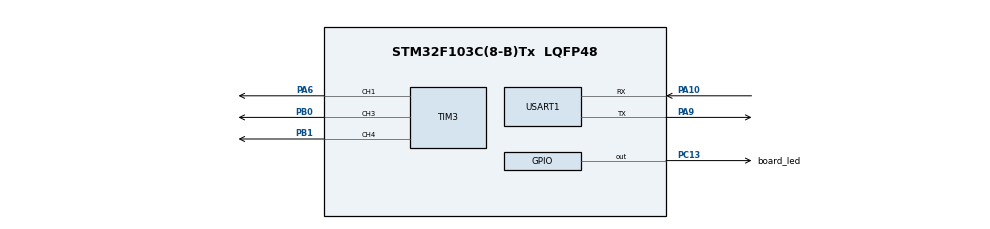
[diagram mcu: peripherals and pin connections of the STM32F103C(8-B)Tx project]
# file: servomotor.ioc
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Dma.Request0=TIM3_CH4/UP
Dma.TIM3_CH4/UP.0.Direction=DMA_PERIPH_TO_MEMORY
Dma.TIM3_CH4/UP.0.Instance=DMA1_Channel3
Dma.TIM3_CH4/UP.0.MemDataAlignment=DMA_MDATAALIGN_HALFWORD
Dma.TIM3_CH4/UP.0.MemInc=DMA_MINC_ENABLE
Dma.TIM3_CH4/UP.0.Mode=DMA_CIRCULAR
Dma.TIM3_CH4/UP.0.PeriphDataAlignment=DMA_PDATAALIGN_HALFWORD
Dma.TIM3_CH4/UP.0.PeriphInc=DMA_PINC_DISABLE
Dma.TIM3_CH4/UP.0.Priority=DMA_PRIORITY_LOW
Mcu.Family=STM32F1
Mcu.Name=STM32F103C(8-B)Tx
Mcu.Package=LQFP48
NVIC.DMA1_Channel3_IRQn=true\:0\:0\:false\:false\:true\:false\:true
NVIC.PriorityGroup=NVIC_PRIORITYGROUP_4
PA10.Mode=Asynchronous
PA10.Signal=USART1_RX
PA13.Mode=Serial_Wire
PA13.Signal=SYS_JTMS-SWDIO
PA14.Mode=Serial_Wire
PA14.Signal=SYS_JTCK-SWCLK
PA6.Signal=S_TIM3_CH1
PA9.Mode=Asynchronous
PA9.Signal=USART1_TX
PB0.Signal=S_TIM3_CH3
PB1.Signal=S_TIM3_CH4
PC13-TAMPER-RTC.GPIO_Label=board_led
PC13-TAMPER-RTC.Signal=GPIO_Output
ProjectManager.HeapSize=0x200
ProjectManager.StackSize=0x400
ProjectManager.TargetToolchain=STM32CubeIDE
RCC.APB1Freq_Value=8000000
RCC.APB2Freq_Value=8000000
SH.S_TIM3_CH1.0=TIM3_CH1,PWM Generation1 CH1
SH.S_TIM3_CH3.0=TIM3_CH3,PWM Generation3 CH3
SH.S_TIM3_CH4.0=TIM3_CH4,PWM Generation4 CH4
TIM3.Channel-PWM\ Generation1\ CH1=TIM_CHANNEL_1
TIM3.Channel-PWM\ Generation3\ CH3=TIM_CHANNEL_3
TIM3.Channel-PWM\ Generation4\ CH4=TIM_CHANNEL_4
USART1.VirtualMode=VM_ASYNC
VP_TIM3_VS_ClockSourceINT.Mode=Internal
board=custom

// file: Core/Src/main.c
/* USER CODE BEGIN Header */
/**
  ******************************************************************************
  * @file           : main.c
  * @brief          : Main program body
  ******************************************************************************
  * @attention
  *
  * <h2><center>&copy; Copyright (c) 2020 STMicroelectronics.
  * All rights reserved.</center></h2>
  *
  * This software component is licensed by ST under BSD 3-Clause license,
  * the "License"; You may not use this file except in compliance with the
  * License. You may obtain a copy of the License at:
  *                        opensource.org/licenses/BSD-3-Clause
  *
  ******************************************************************************
  */
/* USER CODE END Header */

#include "main.h"

TIM_HandleTypeDef htim3;
DMA_HandleTypeDef hdma_tim3_ch4_up;

UART_HandleTypeDef huart1;

void SystemClock_Config(void);
static void MX_GPIO_Init(void);
static void MX_DMA_Init(void);
static void MX_TIM3_Init(void);
static void MX_USART1_UART_Init(void);

int main(void)
{

  /* MCU Configuration--------------------------------------------------------*/

  /* Reset of all peripherals, Initializes the Flash interface and the Systick. */
  HAL_Init();

  /* Configure the system clock */
  SystemClock_Config();

  /* Initialize all configured peripherals */
  MX_GPIO_Init();
  MX_DMA_Init();
  MX_TIM3_Init();
  MX_USART1_UART_Init();
  /* USER CODE BEGIN 2 */

  //  TIM3->CCR3 = 15;
  	htim3.Instance->CCR3 = 600;
  	HAL_TIM_Base_Start(&htim3);
//  	printf("Program start [%s]\r\n", __DATE__);

  	//uint32_t loop_counter = 1000;
//  	HAL_UART_Receive_IT(&huart1, (uint8_t * )rx_temp, 1);
  	HAL_TIM_PWM_Start(&htim3, TIM_CHANNEL_3);

  /* USER CODE END 2 */

  /* Infinite loop */
  while (1)
  {

  }
}

void SystemClock_Config(void)
{
  RCC_OscInitTypeDef RCC_OscInitStruct = {0};
  RCC_ClkInitTypeDef RCC_ClkInitStruct = {0};

  /** Initializes the CPU, AHB and APB busses clocks
  */
  RCC_OscInitStruct.OscillatorType = RCC_OSCILLATORTYPE_HSI;
  RCC_OscInitStruct.HSIState = RCC_HSI_ON;
  RCC_OscInitStruct.HSICalibrationValue = RCC_HSICALIBRATION_DEFAULT;
  RCC_OscInitStruct.PLL.PLLState = RCC_PLL_NONE;
  if (HAL_RCC_OscConfig(&RCC_OscInitStruct) != HAL_OK)
  {
    Error_Handler();
  }
  /** Initializes the CPU, AHB and APB busses clocks
  */
  RCC_ClkInitStruct.ClockType = RCC_CLOCKTYPE_HCLK|RCC_CLOCKTYPE_SYSCLK
                              |RCC_CLOCKTYPE_PCLK1|RCC_CLOCKTYPE_PCLK2;
  RCC_ClkInitStruct.SYSCLKSource = RCC_SYSCLKSOURCE_HSI;
  RCC_ClkInitStruct.AHBCLKDivider = RCC_SYSCLK_DIV1;
  RCC_ClkInitStruct.APB1CLKDivider = RCC_HCLK_DIV1;
  RCC_ClkInitStruct.APB2CLKDivider = RCC_HCLK_DIV1;

  if (HAL_RCC_ClockConfig(&RCC_ClkInitStruct, FLASH_LATENCY_0) != HAL_OK)
  {
    Error_Handler();
  }
}

static void MX_TIM3_Init(void)
{

  TIM_ClockConfigTypeDef sClockSourceConfig = {0};
  TIM_MasterConfigTypeDef sMasterConfig = {0};
  TIM_OC_InitTypeDef sConfigOC = {0};

  htim3.Instance = TIM3;
  htim3.Init.Prescaler = 8;
  htim3.Init.CounterMode = TIM_COUNTERMODE_UP;
  htim3.Init.Period = 20000-1;
  htim3.Init.ClockDivision = TIM_CLOCKDIVISION_DIV1;
  htim3.Init.AutoReloadPreload = TIM_AUTORELOAD_PRELOAD_DISABLE;
  if (HAL_TIM_Base_Init(&htim3) != HAL_OK)
  {
    Error_Handler();
  }
  sClockSourceConfig.ClockSource = TIM_CLOCKSOURCE_INTERNAL;
  if (HAL_TIM_ConfigClockSource(&htim3, &sClockSourceConfig) != HAL_OK)
  {
    Error_Handler();
  }
  if (HAL_TIM_PWM_Init(&htim3) != HAL_OK)
  {
    Error_Handler();
  }
  sMasterConfig.MasterOutputTrigger = TIM_TRGO_RESET;
  sMasterConfig.MasterSlaveMode = TIM_MASTERSLAVEMODE_DISABLE;
  if (HAL_TIMEx_MasterConfigSynchronization(&htim3, &sMasterConfig) != HAL_OK)
  {
    Error_Handler();
  }
  sConfigOC.OCMode = TIM_OCMODE_PWM1;
  sConfigOC.Pulse = 0;
  sConfigOC.OCPolarity = TIM_OCPOLARITY_HIGH;
  sConfigOC.OCFastMode = TIM_OCFAST_DISABLE;
  if (HAL_TIM_PWM_ConfigChannel(&htim3, &sConfigOC, TIM_CHANNEL_1) != HAL_OK)
  {
    Error_Handler();
  }
  if (HAL_TIM_PWM_ConfigChannel(&htim3, &sConfigOC, TIM_CHANNEL_3) != HAL_OK)
  {
    Error_Handler();
  }
  if (HAL_TIM_PWM_ConfigChannel(&htim3, &sConfigOC, TIM_CHANNEL_4) != HAL_OK)
  {
    Error_Handler();
  }
  HAL_TIM_MspPostInit(&htim3);

}

static void MX_USART1_UART_Init(void)
{

  huart1.Instance = USART1;
  huart1.Init.BaudRate = 115200;
  huart1.Init.WordLength = UART_WORDLENGTH_8B;
  huart1.Init.StopBits = UART_STOPBITS_1;
  huart1.Init.Parity = UART_PARITY_NONE;
  huart1.Init.Mode = UART_MODE_TX_RX;
  huart1.Init.HwFlowCtl = UART_HWCONTROL_NONE;
  huart1.Init.OverSampling = UART_OVERSAMPLING_16;
  if (HAL_UART_Init(&huart1) != HAL_OK)
  {
    Error_Handler();
  }

}

static void MX_DMA_Init(void)
{

  /* DMA controller clock enable */
  __HAL_RCC_DMA1_CLK_ENABLE();

  /* DMA interrupt init */
  /* DMA1_Channel3_IRQn interrupt configuration */
  HAL_NVIC_SetPriority(DMA1_Channel3_IRQn, 0, 0);
  HAL_NVIC_EnableIRQ(DMA1_Channel3_IRQn);

}

static void MX_GPIO_Init(void)
{
  GPIO_InitTypeDef GPIO_InitStruct = {0};

  /* GPIO Ports Clock Enable */
  __HAL_RCC_GPIOC_CLK_ENABLE();
  __HAL_RCC_GPIOA_CLK_ENABLE();
  __HAL_RCC_GPIOB_CLK_ENABLE();

  /*Configure GPIO pin Output Level */
  HAL_GPIO_WritePin(board_led_GPIO_Port, board_led_Pin, GPIO_PIN_RESET);

  /*Configure GPIO pin : board_led_Pin */
  GPIO_InitStruct.Pin = board_led_Pin;
  GPIO_InitStruct.Mode = GPIO_MODE_OUTPUT_PP;
  GPIO_InitStruct.Pull = GPIO_NOPULL;
  GPIO_InitStruct.Speed = GPIO_SPEED_FREQ_LOW;
  HAL_GPIO_Init(board_led_GPIO_Port, &GPIO_InitStruct);

}

void Error_Handler(void)
{
}

/************************ (C) COPYRIGHT STMicroelectronics *****END OF FILE****/
